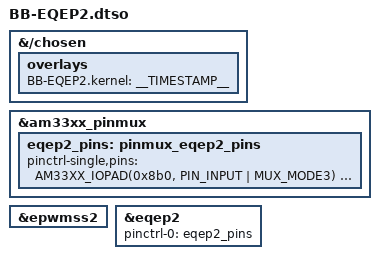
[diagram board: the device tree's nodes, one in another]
// SPDX-License-Identifier: GPL-2.0-only
/*
 * Copyright (C) 2025 Robert Nelson <robertcnelson@gmail.com>
 */

/dts-v1/;
/plugin/;

#include <dt-bindings/pinctrl/am33xx.h>

/*
 * Helper to show loaded overlays under: /proc/device-tree/chosen/overlays/
 */
&{/chosen} {
	overlays {
		BB-EQEP2.kernel = __TIMESTAMP__;
	};
};

&am33xx_pinmux {
	eqep2_pins: pinmux_eqep2_pins {
		pinctrl-single,pins = <
			AM33XX_IOPAD(0x8b0, PIN_INPUT | MUX_MODE3) /* (T1) lcd_data4.eQEP2A_in */
			AM33XX_IOPAD(0x8b4, PIN_INPUT | MUX_MODE3) /* (T2) lcd_data5.eQEP2B_in */
			AM33XX_IOPAD(0x8b8, PIN_INPUT | MUX_MODE3) /* (T3) lcd_data6.eQEP2_index */
			AM33XX_IOPAD(0x8bc, PIN_INPUT | MUX_MODE3) /* (T4) lcd_data7.eQEP2_strobe */
		>;
	};
};

&epwmss2 {
	status = "okay";
};

&eqep2 {
	status = "okay";
	pinctrl-names = "default";
	pinctrl-0 = <&eqep2_pins>;
};
